# Port_D_4 register map
Vendor: Texas Instruments
Peripheral module from a debugger description file (folder msp430).
Registers are 16-bit, read-write, reset 0x0 unless marked. A register's access mark holds for its fields unless they carry their own. Offsets are as the file gives them; lines under a group give offsets from that group; [hi:lo] are bit positions; {n}, {i} and the like mark numbered series; 'fields as' and 'values as' point back to an identical list; <NAME> marks a mode.

## Port_D
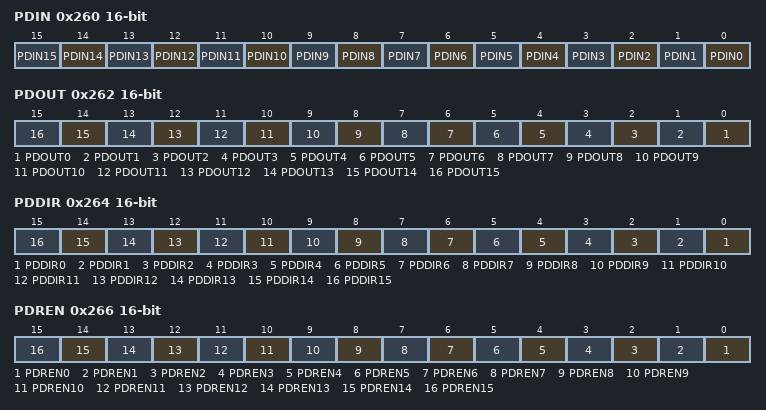
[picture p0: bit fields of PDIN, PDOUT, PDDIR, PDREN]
0x260 PDIN — Port D Input
  [n] PDIN{n} (n=0..15)
0x262 PDOUT — Port D Output
  [n] PDOUT{n} (n=0..15)
0x264 PDDIR — Port D Direction
  [n] PDDIR{n} (n=0..15)
0x266 PDREN — Port D Resistor Enable
  [n] PDREN{n} (n=0..15)
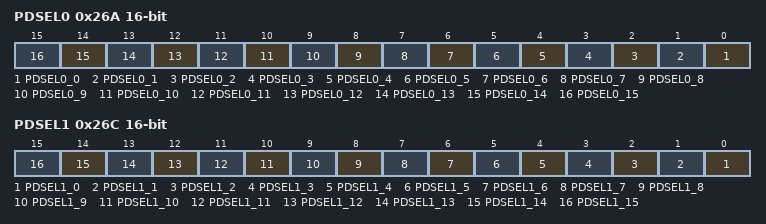
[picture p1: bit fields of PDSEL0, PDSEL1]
0x26A PDSEL0 — Port D Selection 0
  [n] PDSEL0_{n} (n=0..15)
0x26C PDSEL1 — Port D Selection 1
  [n] PDSEL1_{n} (n=0..15)
0x276 PDSELC access not given reset not defined — Port D Complement Selection
